# MCXN947_cm33_core0 register map
Vendor: nxp.com; File version: 1.0
CPU: CM33 r2p0, little endian, MPU, FPU, VTOR, 3 interrupt priority bits
Registers are 32-bit, read-write, reset 0x0 unless marked. A register's access mark holds for its fields unless they carry their own. Offsets are from the block's base; [hi:lo] are bit positions; 'fields as' and 'values as' point back to an identical list.

## CDOG0 — CDOG
Base 0x400BB000
Same registers: CDOG1 0x400BC000
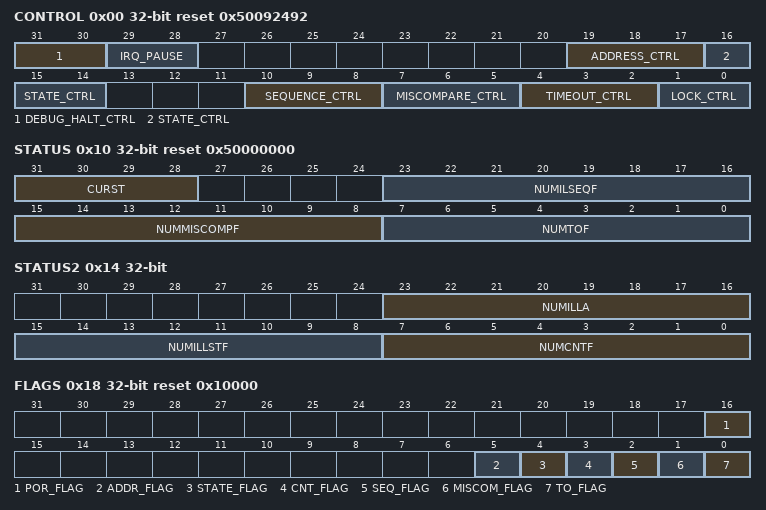
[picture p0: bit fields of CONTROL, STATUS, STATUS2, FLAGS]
0x00 CONTROL reset 0x50092492
  [31:30] DEBUG_HALT_CTRL — DEBUG_HALT control
    1=RUN_TIMER (Keep the timer running); 2=PAUSE_TIMER (Stop the timer)
  [29:28] IRQ_PAUSE — IRQ pause control
    values as DEBUG_HALT_CTRL
  [19:17] ADDRESS_CTRL — ADDRESS fault control
    1=ENABLE_RESET; 2=ENABLE_INTERRUPT; 4=DISABLE_BOTH (Disable both reset and interrupt)
  [16:14] STATE_CTRL — STATE fault control
    values as ADDRESS_CTRL
  [10:8] SEQUENCE_CTRL — SEQUENCE fault control
    values as ADDRESS_CTRL
  [7:5] MISCOMPARE_CTRL — MISCOMPARE fault control
    values as ADDRESS_CTRL
  [4:2] TIMEOUT_CTRL — TIMEOUT fault control
    values as ADDRESS_CTRL
  [1:0] LOCK_CTRL — Lock control
    1=LOCKED; 2=UNLOCKED
0x04 RELOAD reset 0xFFFFFFFF — Instruction Timer Reload Register
  [31:0] RLOAD — Instruction Timer reload value
0x08 INSTRUCTION_TIMER ro reset 0xFFFFFFFF
  [31:0] INSTIM — Current value of the Instruction Timer
0x10 STATUS ro reset 0x50000000 — Status 1 Register
  [31:28] CURST — Current State
  [23:16] NUMILSEQF — Number of SEQUENCE faults since the last POR
  [15:8] NUMMISCOMPF — Number of MISCOMPARE faults since the last POR
  [7:0] NUMTOF — Number of TIMEOUT faults since the last POR
0x14 STATUS2 ro
  [23:16] NUMILLA — Number of ADDRESS faults since the last POR
  [15:8] NUMILLSTF — Number of STATE faults since the last POR
  [7:0] NUMCNTF — Number of CONTROL faults since the last POR
0x18 FLAGS reset 0x10000 write-1-clears
  [16] POR_FLAG write-1-clears — Power-on reset flag
    0=NO_FLAG (A Power-on reset event has not occurred); 1=FLAG (A Power-on reset event has occurred)
  [5] ADDR_FLAG write-1-clears — ADDRESS fault flag
    0=NO_FLAG (An ADDRESS fault has not occurred); 1=FLAG (An ADDRESS fault has occurred)
  [4] STATE_FLAG write-1-clears — STATE fault flag
    0=NO_FLAG (A STATE fault has not occurred); 1=FLAG (A STATE fault has occurred)
  [3] CNT_FLAG write-1-clears — CONTROL fault flag
    0=NO_FLAG (A CONTROL fault has not occurred); 1=FLAG (A CONTROL fault has occurred)
  [2] SEQ_FLAG write-1-clears — SEQUENCE fault flag
    0=NO_FLAG (A SEQUENCE fault has not occurred); 1=FLAG (A SEQUENCE fault has occurred)
  [1] MISCOM_FLAG write-1-clears — MISCOMPARE fault flag
    0=NO_FLAG (A MISCOMPARE fault has not occurred); 1=FLAG (A MISCOMPARE fault has occurred)
  [0] TO_FLAG write-1-clears — TIMEOUT fault flag
    0=NO_FLAG (A TIMEOUT fault has not occurred); 1=FLAG (A TIMEOUT fault has occurred)
0x1C PERSISTENT — Persistent Data Storage Register
  [31:0] PERSIS — Persistent Storage
0x20 START wo — START Command Register
  [31:0] STRT — Start command
0x24 STOP wo — STOP Command Register
  [31:0] STP — Stop command
0x28 RESTART wo — RESTART Command Register
  [31:0] RSTRT — Restart command
0x2C ADD wo — ADD Command Register
  [31:0] AD — ADD Write Value
0x30 ADD1 wo — ADD1 Command Register
  [31:0] AD1 — ADD 1
0x34 ADD16 wo — ADD16 Command Register
  [31:0] AD16 — ADD 16
0x38 ADD256 wo — ADD256 Command Register
  [31:0] AD256 — ADD 256
0x3C SUB wo — SUB Command Register
  [31:0] SB — Subtract Write Value
0x40 SUB1 wo — SUB1 Command Register
  [31:0] SB1 — Subtract 1
0x44 SUB16 wo — SUB16 Command Register
  [31:0] SB16 — Subtract 16
0x48 SUB256 wo — SUB256 Command Register
  [31:0] SB256 — Subtract 256
0x4C ASSERT16 wo — ASSERT16 Command Register
  [31:0] AST16 — ASSERT16 Command

## DM0 — DBGMB
Base 0x400BD000
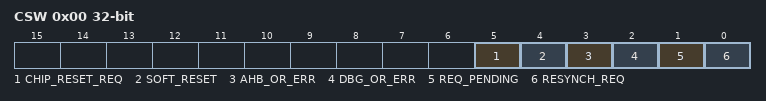
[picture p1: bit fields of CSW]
0x00 CSW — Command and Status Word
  [5] CHIP_RESET_REQ — Chip Reset Request
  [4] SOFT_RESET
  [3] AHB_OR_ERR — AHB Overrun Error
    0=NO_AHB_OVERRUN_ERR (No AHB Overrun Error); 1=AHB_OVERRUN_ERR (AHB Overrun Error. An AHB overrun occurred.)
  [2] DBG_OR_ERR — DBGMB Overrun Error
    0=NO_OVERRUN_ERR (No DBGMB Overrun error); 1=OVERRUN_ERR (DBGMB overrun error. A DBGMB overrun occurred.)
  [1] REQ_PENDING — Request Pending
    0=NO_REQUEST_PENDING; 1=REQUEST_PENDING (Request for resynchronization pending)
  [0] RESYNCH_REQ — Resynchronization Request
    0=NO_REQUEST; 1=REQUEST (Request for resynchronization)
0x04 REQUEST — Request Value
0x08 RETURN — Return Value
  [31:0] RET
0xFC ID ro reset 0x2A0000 — Identification
  [31:0] ID — Identification Value
